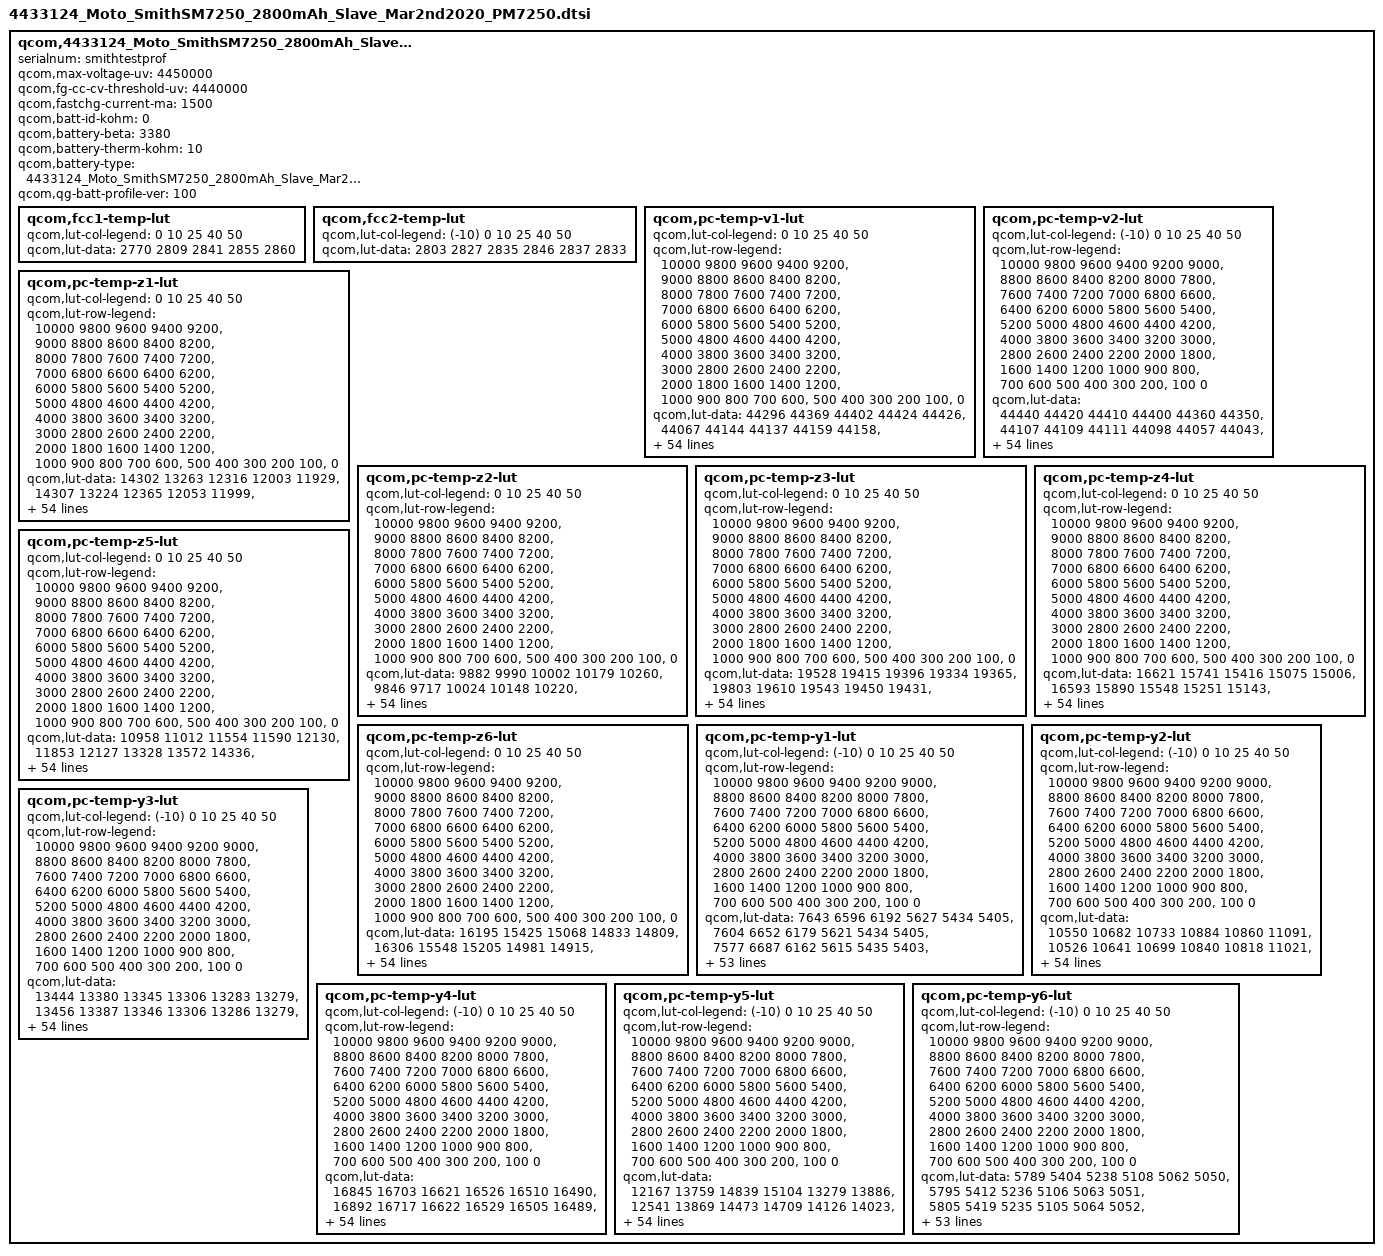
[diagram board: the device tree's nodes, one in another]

qcom,4433124_Moto_SmithSM7250_2800mAh_Slave_Mar2nd2020 {
    /* 4433124_Moto_SmithSM7250_2800mAh_Slave_Mar2nd2020 */
    serialnum = "smithtestprof";
    qcom,max-voltage-uv = <4450000>;
    qcom,fg-cc-cv-threshold-uv = <4440000>;
    qcom,fastchg-current-ma = <1500>;
    qcom,batt-id-kohm = <0>;
    qcom,battery-beta = <3380>;
    qcom,battery-therm-kohm = <10>;
    qcom,battery-type = "4433124_Moto_SmithSM7250_2800mAh_Slave_Mar2nd2020";
    qcom,qg-batt-profile-ver = <100>;

	qcom,fcc1-temp-lut {
		qcom,lut-col-legend = <0 10 25 40 50>;
		qcom,lut-data = <2770 2809 2841 2855 2860>;
	};

	qcom,fcc2-temp-lut {
		qcom,lut-col-legend = <(-10) 0 10 25 40 50>;
		qcom,lut-data = <2803 2827 2835 2846 2837 2833>;
	};

	qcom,pc-temp-v1-lut {
		qcom,lut-col-legend = <0 10 25 40 50>;
		qcom,lut-row-legend = <10000 9800 9600 9400 9200>,
			<9000 8800 8600 8400 8200>,
			<8000 7800 7600 7400 7200>,
			<7000 6800 6600 6400 6200>,
			<6000 5800 5600 5400 5200>,
			<5000 4800 4600 4400 4200>,
			<4000 3800 3600 3400 3200>,
			<3000 2800 2600 2400 2200>,
			<2000 1800 1600 1400 1200>,
			<1000 900 800 700 600>,
			<500 400 300 200 100>,
			<0>;
		qcom,lut-data = <44296 44369 44402 44424 44426>,
			<44067 44144 44137 44159 44158>,
			<43838 43911 43909 43924 43924>,
			<43610 43681 43691 43700 43703>,
			<43383 43456 43465 43477 43481>,
			<43147 43227 43236 43256 43263>,
			<42902 42988 43002 43030 43039>,
			<42657 42744 42760 42793 42805>,
			<42412 42500 42516 42552 42566>,
			<42168 42258 42275 42311 42326>,
			<41935 42020 42036 42069 42084>,
			<41713 41785 41800 41832 41847>,
			<41494 41554 41567 41602 41618>,
			<41275 41330 41339 41376 41393>,
			<41056 41112 41119 41155 41171>,
			<40843 40901 40907 40938 40954>,
			<40634 40694 40702 40732 40746>,
			<40432 40491 40503 40535 40550>,
			<40246 40301 40313 40346 40361>,
			<40068 40124 40137 40166 40183>,
			<39894 39947 39964 39992 40012>,
			<39728 39758 39763 39793 39814>,
			<39554 39563 39530 39553 39570>,
			<39339 39348 39308 39325 39336>,
			<39095 39091 39099 39131 39145>,
			<38909 38880 38914 38960 38979>,
			<38777 38762 38789 38832 38853>,
			<38672 38675 38696 38736 38758>,
			<38588 38592 38611 38647 38667>,
			<38521 38512 38528 38552 38563>,
			<38459 38439 38450 38462 38460>,
			<38398 38371 38374 38377 38371>,
			<38343 38309 38301 38297 38294>,
			<38293 38251 38234 38222 38218>,
			<38249 38200 38172 38151 38140>,
			<38207 38151 38113 38084 38063>,
			<38172 38106 38061 38021 37992>,
			<38134 38062 38014 37962 37926>,
			<38078 38002 37952 37892 37848>,
			<37997 37923 37866 37803 37749>,
			<37901 37828 37764 37701 37636>,
			<37782 37714 37655 37587 37517>,
			<37641 37576 37529 37456 37384>,
			<37473 37405 37368 37296 37221>,
			<37316 37249 37212 37152 37081>,
			<37197 37139 37101 37048 36986>,
			<37170 37107 37071 37013 36954>,
			<37135 37080 37048 36995 36933>,
			<37106 37059 37030 36975 36912>,
			<37075 37027 36989 36926 36853>,
			<36956 36866 36787 36685 36593>,
			<36561 36441 36356 36247 36153>,
			<35992 35856 35778 35669 35574>,
			<35200 35022 34993 34884 34787>,
			<33836 33705 33780 33679 33580>,
			<30000 30000 30000 30000 30000>;
	};

	qcom,pc-temp-v2-lut {
		qcom,lut-col-legend = <(-10) 0 10 25 40 50>;
		qcom,lut-row-legend = <10000 9800 9600 9400 9200 9000>,
			<8800 8600 8400 8200 8000 7800>,
			<7600 7400 7200 7000 6800 6600>,
			<6400 6200 6000 5800 5600 5400>,
			<5200 5000 4800 4600 4400 4200>,
			<4000 3800 3600 3400 3200 3000>,
			<2800 2600 2400 2200 2000 1800>,
			<1600 1400 1200 1000 900 800>,
			<700 600 500 400 300 200>,
			<100 0>;
		qcom,lut-data = <44440 44420 44410 44400 44360 44350>,
			<44107 44109 44111 44098 44057 44043>,
			<43809 43827 43837 43820 43777 43760>,
			<43554 43578 43590 43567 43522 43504>,
			<43338 43362 43371 43340 43294 43274>,
			<43122 43142 43149 43111 43065 43045>,
			<42889 42902 42911 42871 42826 42809>,
			<42649 42656 42668 42628 42585 42570>,
			<42411 42412 42424 42383 42343 42330>,
			<42170 42168 42177 42138 42100 42088>,
			<41930 41928 41933 41896 41860 41850>,
			<41692 41690 41692 41659 41623 41615>,
			<41454 41457 41456 41426 41391 41386>,
			<41213 41231 41225 41197 41163 41160>,
			<40970 41011 41001 40972 40941 40939>,
			<40726 40791 40782 40755 40727 40725>,
			<40479 40570 40573 40546 40521 40517>,
			<40231 40344 40367 40343 40323 40317>,
			<39986 40101 40164 40152 40136 40129>,
			<39738 39842 39963 39968 39956 39950>,
			<39516 39602 39745 39769 39764 39762>,
			<39332 39384 39491 39546 39553 39557>,
			<39169 39186 39247 39324 39338 39349>,
			<39006 39008 39051 39107 39126 39138>,
			<38846 38847 38879 38899 38918 38927>,
			<38697 38702 38728 38736 38753 38760>,
			<38558 38571 38593 38606 38625 38634>,
			<38428 38452 38474 38494 38514 38524>,
			<38307 38341 38367 38390 38410 38419>,
			<38192 38238 38271 38296 38315 38321>,
			<38091 38143 38182 38209 38229 38233>,
			<38000 38055 38098 38128 38152 38156>,
			<37922 37975 38019 38052 38077 38078>,
			<37862 37907 37946 37983 37999 37993>,
			<37815 37846 37876 37916 37920 37904>,
			<37771 37795 37814 37841 37834 37808>,
			<37728 37755 37759 37761 37743 37705>,
			<37685 37714 37701 37679 37649 37601>,
			<37635 37660 37636 37598 37554 37502>,
			<37579 37594 37564 37513 37458 37404>,
			<37505 37514 37478 37421 37363 37307>,
			<37376 37407 37371 37318 37270 37211>,
			<37236 37275 37239 37181 37136 37082>,
			<37126 37113 37092 37052 36990 36934>,
			<37016 36974 36977 36970 36922 36865>,
			<36916 36868 36889 36897 36850 36794>,
			<36865 36823 36859 36876 36834 36774>,
			<36819 36785 36834 36857 36826 36777>,
			<36770 36734 36796 36835 36801 36740>,
			<36712 36650 36713 36756 36713 36648>,
			<36627 36439 36462 36459 36409 36299>,
			<36430 35983 35933 35938 35903 35798>,
			<35958 35298 35228 35265 35248 35138>,
			<35225 34276 34232 34311 34366 34251>,
			<34124 32807 32852 33186 33117 32969>,
			<32439 30056 29520 29519 29517 29516>;
	};

	qcom,pc-temp-z1-lut {
		qcom,lut-col-legend = <0 10 25 40 50>;
		qcom,lut-row-legend = <10000 9800 9600 9400 9200>,
			<9000 8800 8600 8400 8200>,
			<8000 7800 7600 7400 7200>,
			<7000 6800 6600 6400 6200>,
			<6000 5800 5600 5400 5200>,
			<5000 4800 4600 4400 4200>,
			<4000 3800 3600 3400 3200>,
			<3000 2800 2600 2400 2200>,
			<2000 1800 1600 1400 1200>,
			<1000 900 800 700 600>,
			<500 400 300 200 100>,
			<0>;
		qcom,lut-data = <14302 13263 12316 12003 11929>,
			<14307 13224 12365 12053 11999>,
			<14308 13223 12361 12056 12003>,
			<14288 13219 12354 12057 12006>,
			<14247 13200 12346 12057 12006>,
			<14219 13176 12337 12054 12003>,
			<14200 13158 12329 12051 12002>,
			<14181 13141 12320 12051 12002>,
			<14155 13124 12314 12050 12003>,
			<14127 13103 12311 12050 12002>,
			<14105 13088 12309 12049 12001>,
			<14086 13082 12307 12048 12001>,
			<14069 13079 12305 12047 12001>,
			<14050 13075 12305 12047 12001>,
			<14032 13072 12305 12047 12002>,
			<14015 13068 12305 12048 12003>,
			<13998 13061 12305 12049 12004>,
			<13988 13053 12306 12050 12005>,
			<13988 13050 12307 12052 12007>,
			<13989 13049 12308 12054 12009>,
			<13991 13049 12309 12055 12011>,
			<13993 13052 12310 12057 12013>,
			<13995 13057 12313 12059 12015>,
			<14001 13063 12317 12060 12017>,
			<14011 13068 12320 12063 12019>,
			<14019 13074 12324 12066 12021>,
			<14027 13081 12329 12069 12023>,
			<14032 13089 12336 12073 12026>,
			<14031 13096 12343 12076 12030>,
			<14025 13102 12350 12080 12033>,
			<14022 13109 12356 12085 12036>,
			<14026 13119 12363 12089 12040>,
			<14033 13131 12369 12093 12043>,
			<14039 13141 12376 12097 12047>,
			<14047 13149 12382 12102 12052>,
			<14056 13159 12389 12107 12056>,
			<14071 13169 12396 12111 12059>,
			<14090 13181 12403 12115 12061>,
			<14111 13195 12410 12118 12064>,
			<14134 13211 12419 12122 12067>,
			<14162 13227 12428 12126 12070>,
			<14198 13240 12436 12130 12073>,
			<14239 13253 12444 12134 12076>,
			<14295 13280 12452 12136 12077>,
			<14290 13295 12463 12139 12078>,
			<14281 13298 12471 12142 12079>,
			<14282 13302 12470 12141 12079>,
			<14305 13310 12469 12142 12079>,
			<14319 13306 12473 12142 12081>,
			<14309 13346 12483 12146 12083>,
			<14370 13349 12494 12150 12086>,
			<14367 13369 12504 12158 12092>,
			<14396 13413 12520 12166 12099>,
			<14439 13440 12546 12181 12112>,
			<14439 13440 12546 12181 12112>,
			<14439 13440 12546 12181 12112>;
	};

	qcom,pc-temp-z2-lut {
		qcom,lut-col-legend = <0 10 25 40 50>;
		qcom,lut-row-legend = <10000 9800 9600 9400 9200>,
			<9000 8800 8600 8400 8200>,
			<8000 7800 7600 7400 7200>,
			<7000 6800 6600 6400 6200>,
			<6000 5800 5600 5400 5200>,
			<5000 4800 4600 4400 4200>,
			<4000 3800 3600 3400 3200>,
			<3000 2800 2600 2400 2200>,
			<2000 1800 1600 1400 1200>,
			<1000 900 800 700 600>,
			<500 400 300 200 100>,
			<0>;
		qcom,lut-data = <9882 9990 10002 10179 10260>,
			<9846 9717 10024 10148 10220>,
			<9817 9850 10017 10157 10231>,
			<9793 9894 10004 10160 10234>,
			<9772 9867 9980 10146 10227>,
			<9756 9833 9938 10075 10182>,
			<9742 9809 9903 10027 10143>,
			<9733 9790 9871 10018 10126>,
			<9730 9780 9852 10013 10116>,
			<9728 9775 9860 10014 10118>,
			<9737 9773 9882 10023 10136>,
			<9812 9781 9897 10033 10145>,
			<9872 9803 9905 10045 10144>,
			<9842 9820 9915 10058 10142>,
			<9779 9833 9929 10070 10153>,
			<9761 9844 9947 10081 10187>,
			<9775 9853 9963 10090 10201>,
			<9795 9861 9978 10096 10193>,
			<9814 9872 9993 10103 10178>,
			<9834 9892 10010 10115 10156>,
			<9839 9906 10029 10134 10126>,
			<9836 9905 10063 10183 10142>,
			<9833 9903 10125 10372 10401>,
			<9838 9906 10157 10509 10615>,
			<9854 9943 10147 10425 10553>,
			<9865 9972 10124 10257 10412>,
			<9871 9964 10092 10173 10327>,
			<9876 9947 10042 10125 10271>,
			<9881 9942 10020 10105 10246>,
			<9885 9942 10032 10222 10317>,
			<9889 9943 10054 10390 10425>,
			<9893 9945 10086 10391 10406>,
			<9898 9949 10133 10282 10238>,
			<9900 9953 10149 10201 10129>,
			<9903 9956 10112 10165 10104>,
			<9905 9960 10074 10145 10091>,
			<9906 9965 10078 10161 10109>,
			<9908 9971 10101 10226 10180>,
			<9912 9976 10124 10278 10251>,
			<9918 9982 10151 10308 10313>,
			<9924 9987 10174 10337 10374>,
			<9926 9993 10184 10379 10426>,
			<9929 9998 10190 10421 10476>,
			<9947 10002 10193 10432 10542>,
			<10107 10071 10215 10383 10492>,
			<10204 10143 10245 10280 10312>,
			<10275 10166 10213 10278 10314>,
			<10293 10189 10196 10282 10330>,
			<10290 10389 10156 10284 10361>,
			<10281 10690 10175 10334 10438>,
			<10291 10407 10221 10366 10247>,
			<10166 10282 10150 10162 10093>,
			<9969 10181 10098 10068 10053>,
			<9853 10014 10033 9980 10004>,
			<9853 10014 10033 9980 10004>,
			<9853 10014 10033 9980 10004>;
	};

	qcom,pc-temp-z3-lut {
		qcom,lut-col-legend = <0 10 25 40 50>;
		qcom,lut-row-legend = <10000 9800 9600 9400 9200>,
			<9000 8800 8600 8400 8200>,
			<8000 7800 7600 7400 7200>,
			<7000 6800 6600 6400 6200>,
			<6000 5800 5600 5400 5200>,
			<5000 4800 4600 4400 4200>,
			<4000 3800 3600 3400 3200>,
			<3000 2800 2600 2400 2200>,
			<2000 1800 1600 1400 1200>,
			<1000 900 800 700 600>,
			<500 400 300 200 100>,
			<0>;
		qcom,lut-data = <19528 19415 19396 19334 19365>,
			<19803 19610 19543 19450 19431>,
			<19968 19729 19582 19492 19465>,
			<20030 19784 19604 19522 19484>,
			<20067 19813 19627 19534 19494>,
			<20085 19828 19646 19542 19502>,
			<20095 19832 19651 19545 19505>,
			<20100 19833 19652 19542 19503>,
			<20098 19833 19653 19538 19498>,
			<20095 19820 19642 19533 19494>,
			<20096 19801 19615 19526 19490>,
			<20113 19780 19597 19517 19485>,
			<20127 19757 19588 19505 19475>,
			<20091 19740 19579 19492 19464>,
			<20012 19727 19566 19483 19457>,
			<19973 19719 19552 19476 19451>,
			<19960 19717 19540 19467 19443>,
			<19949 19716 19530 19452 19430>,
			<19923 19713 19521 19437 19415>,
			<19892 19700 19510 19426 19397>,
			<19884 19691 19501 19417 19378>,
			<19907 19694 19504 19418 19376>,
			<19936 19702 19528 19445 19406>,
			<19957 19711 19542 19466 19430>,
			<19975 19724 19539 19457 19423>,
			<19980 19732 19532 19435 19405>,
			<19971 19724 19521 19414 19386>,
			<19956 19705 19502 19390 19360>,
			<19943 19693 19485 19377 19346>,
			<19930 19685 19472 19391 19388>,
			<19921 19680 19463 19416 19450>,
			<19916 19679 19470 19436 19457>,
			<19912 19678 19494 19455 19438>,
			<19908 19678 19510 19463 19420>,
			<19904 19678 19517 19451 19404>,
			<19898 19678 19520 19432 19389>,
			<19892 19676 19513 19418 19377>,
			<19884 19672 19492 19406 19366>,
			<19875 19666 19483 19397 19363>,
			<19864 19659 19482 19391 19364>,
			<19851 19649 19481 19388 19367>,
			<19833 19633 19470 19389 19372>,
			<19810 19617 19453 19392 19381>,
			<19784 19611 19451 19404 19398>,
			<19672 19575 19443 19399 19395>,
			<19594 19527 19428 19367 19357>,
			<19358 19499 19418 19366 19343>,
			<19345 19489 19415 19355 19340>,
			<19334 19367 19397 19349 19335>,
			<19313 19316 19390 19347 19333>,
			<19314 19368 19400 19397 19381>,
			<19344 19387 19448 19415 19389>,
			<19349 19395 19463 19417 19389>,
			<19416 19564 19466 19417 19389>,
			<19416 19564 19466 19417 19389>,
			<19416 19564 19466 19417 19389>;
	};

	qcom,pc-temp-z4-lut {
		qcom,lut-col-legend = <0 10 25 40 50>;
		qcom,lut-row-legend = <10000 9800 9600 9400 9200>,
			<9000 8800 8600 8400 8200>,
			<8000 7800 7600 7400 7200>,
			<7000 6800 6600 6400 6200>,
			<6000 5800 5600 5400 5200>,
			<5000 4800 4600 4400 4200>,
			<4000 3800 3600 3400 3200>,
			<3000 2800 2600 2400 2200>,
			<2000 1800 1600 1400 1200>,
			<1000 900 800 700 600>,
			<500 400 300 200 100>,
			<0>;
		qcom,lut-data = <16621 15741 15416 15075 15006>,
			<16593 15890 15548 15251 15143>,
			<16524 15752 15416 15189 15104>,
			<16320 15610 15238 15066 15002>,
			<16006 15454 15136 14991 14934>,
			<15787 15313 15056 14941 14889>,
			<15627 15218 14993 14897 14851>,
			<15497 15143 14942 14853 14818>,
			<15397 15089 14902 14818 14791>,
			<15313 15048 14876 14803 14778>,
			<15216 15015 14856 14795 14771>,
			<15087 14980 14841 14788 14765>,
			<15009 14948 14828 14781 14758>,
			<15020 14926 14818 14774 14752>,
			<15047 14913 14810 14765 14745>,
			<15052 14900 14802 14756 14737>,
			<15020 14885 14795 14749 14730>,
			<14992 14869 14787 14744 14723>,
			<14994 14857 14779 14740 14719>,
			<14999 14845 14772 14734 14717>,
			<14997 14839 14766 14728 14715>,
			<14946 14843 14773 14730 14718>,
			<14897 14856 14813 14767 14753>,
			<14923 14883 14863 14817 14800>,
			<15000 14967 14926 14878 14854>,
			<15048 15029 14981 14939 14909>,
			<15070 15027 14986 14950 14920>,
			<15082 15017 14979 14948 14917>,
			<15078 15005 14969 14943 14911>,
			<15062 14987 14957 14913 14851>,
			<15045 14967 14941 14861 14763>,
			<15027 14948 14913 14816 14740>,
			<15007 14929 14867 14769 14733>,
			<14991 14910 14832 14749 14731>,
			<14978 14890 14807 14748 14731>,
			<14963 14873 14791 14747 14731>,
			<14946 14861 14788 14746 14730>,
			<14929 14851 14786 14745 14725>,
			<14911 14843 14786 14745 14724>,
			<14893 14836 14794 14764 14742>,
			<14874 14828 14801 14783 14760>,
			<14855 14817 14801 14780 14754>,
			<14833 14803 14800 14768 14736>,
			<14805 14784 14794 14756 14724>,
			<14778 14748 14763 14741 14712>,
			<14785 14730 14731 14733 14711>,
			<15041 14741 14726 14725 14714>,
			<15044 14738 14707 14711 14694>,
			<15048 14861 14694 14682 14663>,
			<15063 14909 14686 14666 14651>,
			<15034 14858 14711 14671 14669>,
			<15070 14869 14693 14681 14682>,
			<15066 14873 14687 14691 14694>,
			<15027 14725 14698 14703 14707>,
			<15027 14725 14698 14703 14707>,
			<15027 14725 14698 14703 14707>;
	};

	qcom,pc-temp-z5-lut {
		qcom,lut-col-legend = <0 10 25 40 50>;
		qcom,lut-row-legend = <10000 9800 9600 9400 9200>,
			<9000 8800 8600 8400 8200>,
			<8000 7800 7600 7400 7200>,
			<7000 6800 6600 6400 6200>,
			<6000 5800 5600 5400 5200>,
			<5000 4800 4600 4400 4200>,
			<4000 3800 3600 3400 3200>,
			<3000 2800 2600 2400 2200>,
			<2000 1800 1600 1400 1200>,
			<1000 900 800 700 600>,
			<500 400 300 200 100>,
			<0>;
		qcom,lut-data = <10958 11012 11554 11590 12130>,
			<11853 12127 13328 13572 14336>,
			<12471 12998 13929 14770 15694>,
			<12788 13574 14366 16000 17129>,
			<13017 13940 14950 16738 18202>,
			<13275 14246 15573 17180 18977>,
			<13546 14604 16181 17706 19800>,
			<13844 14951 16862 18655 20919>,
			<14175 15122 17340 19674 22118>,
			<14562 15180 17450 20318 23158>,
			<15143 15245 17505 20822 24172>,
			<16227 15453 17656 20986 24574>,
			<16963 15827 18154 20788 24289>,
			<16686 16177 18515 20571 23943>,
			<16090 16467 18510 20868 24394>,
			<16011 16832 18490 21729 25911>,
			<16984 17602 18543 21994 26499>,
			<17838 18647 18957 21220 25585>,
			<17511 19116 19440 20505 24097>,
			<16704 19238 19736 20557 22191>,
			<16609 19400 20071 20850 19902>,
			<19338 20748 21787 22154 20159>,
			<23364 23506 27673 29534 29597>,
			<27654 25617 31013 35082 37395>,
			<32431 27441 28760 31294 33374>,
			<33883 28434 24848 23582 24466>,
			<31564 26656 21976 19172 19187>,
			<28469 22944 19446 16227 15653>,
			<26484 21200 17766 14980 14101>,
			<24810 20427 16670 15282 17213>,
			<24212 20082 16015 16017 21928>,
			<24160 20210 16315 17507 22502>,
			<24135 20574 17707 20657 21564>,
			<24190 21107 19416 22260 20851>,
			<24393 22137 22136 22368 20537>,
			<24550 23208 24281 22420 20352>,
			<24609 24150 24091 22363 20355>,
			<24668 24946 23252 22104 20416>,
			<24942 25095 23005 21729 20423>,
			<25650 25023 23707 21014 19994>,
			<26004 24883 24349 20107 19557>,
			<25118 23536 22190 19063 19631>,
			<24404 22086 18674 18171 20048>,
			<24654 23547 19058 20400 25117>,
			<22559 23876 20319 20754 26080>,
			<18802 21370 20566 16935 17505>,
			<11548 17573 18946 17077 15727>,
			<11404 16555 19449 16564 16447>,
			<11287 12036 17893 18226 19370>,
			<11106 11305 17718 19298 20894>,
			<11231 12073 17615 28108 30060>,
			<11289 12281 20912 26954 27485>,
			<11308 12364 22129 24351 24356>,
			<11917 23636 20542 21049 20849>,
			<11917 23636 20542 21049 20849>,
			<11917 23636 20542 21049 20849>;
	};

	qcom,pc-temp-z6-lut {
		qcom,lut-col-legend = <0 10 25 40 50>;
		qcom,lut-row-legend = <10000 9800 9600 9400 9200>,
			<9000 8800 8600 8400 8200>,
			<8000 7800 7600 7400 7200>,
			<7000 6800 6600 6400 6200>,
			<6000 5800 5600 5400 5200>,
			<5000 4800 4600 4400 4200>,
			<4000 3800 3600 3400 3200>,
			<3000 2800 2600 2400 2200>,
			<2000 1800 1600 1400 1200>,
			<1000 900 800 700 600>,
			<500 400 300 200 100>,
			<0>;
		qcom,lut-data = <16195 15425 15068 14833 14809>,
			<16306 15548 15205 14981 14915>,
			<16342 15553 15163 14967 14909>,
			<16275 15550 15107 14937 14880>,
			<16140 15494 15074 14915 14860>,
			<16041 15423 15048 14897 14845>,
			<15963 15380 15025 14880 14831>,
			<15897 15344 15004 14861 14816>,
			<15841 15312 14985 14844 14803>,
			<15792 15284 14963 14833 14794>,
			<15746 15257 14942 14826 14789>,
			<15702 15229 14927 14818 14783>,
			<15663 15201 14916 14808 14774>,
			<15631 15181 14906 14798 14765>,
			<15602 15169 14895 14789 14758>,
			<15577 15158 14884 14781 14751>,
			<15554 15149 14874 14772 14744>,
			<15535 15140 14865 14762 14734>,
			<15521 15131 14857 14752 14724>,
			<15510 15119 14848 14743 14713>,
			<15502 15112 14840 14736 14702>,
			<15495 15116 14844 14737 14702>,
			<15492 15127 14874 14768 14733>,
			<15510 15145 14904 14800 14767>,
			<15559 15190 14930 14819 14785>,
			<15582 15221 14950 14834 14797>,
			<15586 15217 14950 14835 14798>,
			<15589 15206 14937 14823 14785>,
			<15585 15195 14925 14810 14773>,
			<15574 15186 14914 14803 14768>,
			<15563 15177 14903 14797 14765>,
			<15554 15169 14896 14790 14759>,
			<15546 15162 14890 14782 14747>,
			<15540 15155 14884 14775 14737>,
			<15534 15149 14879 14767 14729>,
			<15528 15144 14875 14760 14722>,
			<15522 15140 14867 14752 14714>,
			<15517 15136 14857 14744 14706>,
			<15513 15133 14854 14741 14704>,
			<15510 15131 14858 14746 14712>,
			<15505 15128 14862 14752 14721>,
			<15499 15121 14858 14751 14720>,
			<15491 15112 14850 14748 14719>,
			<15481 15107 14846 14748 14722>,
			<15430 15080 14831 14742 14715>,
			<15401 15052 14811 14721 14695>,
			<15393 15045 14804 14717 14691>,
			<15390 15041 14794 14705 14679>,
			<15389 15033 14780 14689 14663>,
			<15393 15033 14774 14681 14656>,
			<15394 15046 14793 14710 14690>,
			<15439 15068 14813 14727 14703>,
			<15455 15085 14823 14735 14711>,
			<15497 15123 14835 14743 14719>,
			<15497 15123 14835 14743 14719>,
			<15497 15123 14835 14743 14719>;
	};

	qcom,pc-temp-y1-lut {
		qcom,lut-col-legend = <(-10) 0 10 25 40 50>;
		qcom,lut-row-legend = <10000 9800 9600 9400 9200 9000>,
			<8800 8600 8400 8200 8000 7800>,
			<7600 7400 7200 7000 6800 6600>,
			<6400 6200 6000 5800 5600 5400>,
			<5200 5000 4800 4600 4400 4200>,
			<4000 3800 3600 3400 3200 3000>,
			<2800 2600 2400 2200 2000 1800>,
			<1600 1400 1200 1000 900 800>,
			<700 600 500 400 300 200>,
			<100 0>;
		qcom,lut-data = <7643 6596 6192 5627 5434 5405>,
			<7604 6652 6179 5621 5434 5405>,
			<7577 6687 6162 5615 5435 5403>,
			<7560 6706 6144 5610 5435 5402>,
			<7551 6714 6128 5604 5435 5401>,
			<7549 6715 6121 5600 5434 5400>,
			<7559 6700 6119 5595 5433 5400>,
			<7574 6678 6117 5590 5432 5400>,
			<7575 6670 6113 5587 5430 5400>,
			<7563 6666 6105 5585 5429 5400>,
			<7553 6664 6096 5583 5428 5400>,
			<7548 6669 6086 5583 5429 5400>,
			<7545 6676 6077 5582 5430 5400>,
			<7548 6675 6072 5581 5430 5400>,
			<7565 6671 6069 5579 5431 5402>,
			<7576 6669 6065 5578 5431 5402>,
			<7577 6675 6060 5579 5432 5402>,
			<7578 6681 6057 5581 5433 5401>,
			<7575 6678 6058 5583 5433 5402>,
			<7561 6666 6060 5585 5433 5403>,
			<7550 6661 6062 5587 5434 5404>,
			<7546 6661 6065 5589 5435 5405>,
			<7544 6662 6068 5592 5436 5405>,
			<7545 6663 6071 5595 5438 5406>,
			<7554 6666 6075 5598 5440 5408>,
			<7564 6669 6078 5602 5442 5410>,
			<7581 6671 6080 5605 5444 5412>,
			<7598 6673 6082 5609 5447 5413>,
			<7596 6676 6086 5613 5449 5415>,
			<7577 6680 6094 5618 5452 5417>,
			<7566 6685 6101 5622 5454 5419>,
			<7569 6700 6107 5627 5455 5421>,
			<7573 6711 6113 5632 5457 5423>,
			<7571 6709 6116 5639 5460 5426>,
			<7559 6705 6120 5645 5464 5429>,
			<7548 6705 6123 5649 5467 5431>,
			<7543 6716 6125 5652 5468 5432>,
			<7540 6724 6128 5655 5470 5433>,
			<7540 6722 6132 5658 5471 5435>,
			<7542 6718 6136 5661 5473 5435>,
			<7546 6724 6141 5664 5474 5436>,
			<7580 6775 6148 5667 5475 5437>,
			<7607 6786 6155 5668 5477 5438>,
			<7575 6766 6163 5669 5478 5440>,
			<7586 6782 6174 5675 5479 5441>,
			<7625 6782 6195 5677 5482 5443>,
			<7628 6769 6204 5682 5483 5444>,
			<7607 6773 6214 5684 5484 5445>,
			<7619 6795 6218 5685 5485 5445>,
			<7630 6779 6217 5684 5485 5446>,
			<7664 6803 6236 5686 5485 5447>,
			<7816 6811 6246 5694 5490 5450>,
			<7890 6930 6290 5708 5495 5457>,
			<8109 7068 6337 5724 5504 5462>,
			<8109 7068 6337 5724 5504 5462>,
			<8109 7068 6337 5724 5504 5462>;
	};

	qcom,pc-temp-y2-lut {
		qcom,lut-col-legend = <(-10) 0 10 25 40 50>;
		qcom,lut-row-legend = <10000 9800 9600 9400 9200 9000>,
			<8800 8600 8400 8200 8000 7800>,
			<7600 7400 7200 7000 6800 6600>,
			<6400 6200 6000 5800 5600 5400>,
			<5200 5000 4800 4600 4400 4200>,
			<4000 3800 3600 3400 3200 3000>,
			<2800 2600 2400 2200 2000 1800>,
			<1600 1400 1200 1000 900 800>,
			<700 600 500 400 300 200>,
			<100 0>;
		qcom,lut-data = <10550 10682 10733 10884 10860 11091>,
			<10526 10641 10699 10840 10818 11021>,
			<10499 10600 10667 10796 10777 10942>,
			<10473 10563 10637 10756 10739 10865>,
			<10451 10531 10611 10721 10707 10802>,
			<10437 10507 10587 10693 10681 10762>,
			<10429 10486 10566 10670 10662 10743>,
			<10424 10472 10548 10652 10646 10728>,
			<10424 10470 10537 10643 10633 10711>,
			<10426 10469 10530 10638 10621 10691>,
			<10430 10469 10527 10632 10613 10673>,
			<10434 10473 10534 10618 10606 10653>,
			<10439 10480 10544 10607 10602 10639>,
			<10446 10484 10551 10607 10602 10638>,
			<10453 10486 10556 10613 10607 10644>,
			<10465 10491 10564 10622 10615 10653>,
			<10495 10521 10574 10644 10653 10675>,
			<10531 10557 10589 10677 10708 10709>,
			<10539 10568 10614 10727 10755 10745>,
			<10540 10574 10652 10795 10801 10788>,
			<10541 10581 10670 10834 10855 10844>,
			<10546 10594 10675 10857 10932 10945>,
			<10555 10608 10679 10868 10987 11022>,
			<10560 10622 10687 10864 10968 11011>,
			<10565 10637 10699 10856 10918 10975>,
			<10568 10646 10711 10857 10907 10965>,
			<10571 10652 10727 10879 10949 11000>,
			<10572 10656 10737 10904 10994 11049>,
			<10574 10657 10735 10923 11009 11086>,
			<10575 10658 10732 10939 11019 11124>,
			<10577 10658 10731 10950 11041 11177>,
			<10588 10654 10731 10959 11098 11271>,
			<10603 10649 10731 10963 11156 11333>,
			<10598 10644 10729 10956 11199 11312>,
			<10562 10636 10724 10942 11234 11257>,
			<10522 10625 10717 10929 11229 11208>,
			<10489 10604 10710 10916 11164 11154>,
			<10455 10580 10700 10901 11097 11125>,
			<10420 10558 10688 10877 11054 11130>,
			<10388 10534 10672 10857 11021 11140>,
			<10330 10502 10654 10857 11010 11120>,
			<9992 10457 10632 10862 11007 11013>,
			<9712 10401 10601 10830 10972 10999>,
			<9681 10330 10560 10792 10894 11028>,
			<9668 10260 10520 10793 10868 10890>,
			<9663 10174 10475 10733 10809 10827>,
			<9660 9926 10441 10707 10729 10764>,
			<9657 9825 10418 10686 10797 10899>,
			<9655 9741 10404 10728 10865 10945>,
			<9652 9678 10392 10734 10855 10928>,
			<9649 9658 10307 10695 10756 10756>,
			<9647 9651 10144 10644 10710 10731>,
			<9646 9648 9906 10584 10664 10722>,
			<9646 9649 9662 10464 10574 10618>,
			<9646 9649 9662 10464 10574 10618>,
			<9646 9649 9662 10464 10574 10618>;
	};

	qcom,pc-temp-y3-lut {
		qcom,lut-col-legend = <(-10) 0 10 25 40 50>;
		qcom,lut-row-legend = <10000 9800 9600 9400 9200 9000>,
			<8800 8600 8400 8200 8000 7800>,
			<7600 7400 7200 7000 6800 6600>,
			<6400 6200 6000 5800 5600 5400>,
			<5200 5000 4800 4600 4400 4200>,
			<4000 3800 3600 3400 3200 3000>,
			<2800 2600 2400 2200 2000 1800>,
			<1600 1400 1200 1000 900 800>,
			<700 600 500 400 300 200>,
			<100 0>;
		qcom,lut-data = <13444 13380 13345 13306 13283 13279>,
			<13456 13387 13346 13306 13286 13279>,
			<13472 13397 13348 13306 13288 13280>,
			<13489 13406 13349 13306 13291 13281>,
			<13503 13413 13351 13306 13293 13282>,
			<13511 13416 13353 13306 13294 13283>,
			<13513 13415 13356 13308 13295 13284>,
			<13515 13413 13358 13310 13297 13286>,
			<13518 13414 13358 13312 13297 13286>,
			<13523 13419 13358 13312 13298 13287>,
			<13527 13423 13358 13314 13299 13288>,
			<13531 13424 13358 13320 13299 13290>,
			<13534 13425 13358 13327 13299 13293>,
			<13534 13428 13358 13328 13300 13294>,
			<13535 13437 13361 13327 13300 13294>,
			<13535 13441 13365 13328 13300 13295>,
			<13525 13443 13372 13330 13305 13295>,
			<13507 13444 13377 13333 13311 13295>,
			<13494 13440 13378 13333 13314 13297>,
			<13482 13425 13377 13333 13315 13302>,
			<13475 13412 13375 13333 13315 13304>,
			<13473 13403 13366 13329 13310 13303>,
			<13472 13395 13354 13324 13303 13299>,
			<13469 13389 13349 13315 13297 13293>,
			<13465 13385 13345 13304 13290 13284>,
			<13461 13383 13341 13300 13288 13281>,
			<13455 13382 13336 13299 13287 13283>,
			<13449 13382 13333 13298 13287 13284>,
			<13443 13382 13335 13300 13286 13284>,
			<13439 13381 13339 13303 13285 13282>,
			<13433 13381 13340 13304 13285 13282>,
			<13418 13382 13340 13304 13285 13283>,
			<13403 13383 13340 13304 13286 13284>,
			<13402 13382 13340 13304 13287 13284>,
			<13414 13380 13340 13303 13287 13284>,
			<13429 13380 13341 13303 13287 13284>,
			<13444 13384 13341 13303 13287 13282>,
			<13459 13389 13341 13304 13286 13280>,
			<13475 13394 13343 13304 13286 13281>,
			<13491 13398 13345 13305 13286 13282>,
			<13498 13402 13346 13306 13288 13284>,
			<13492 13407 13346 13307 13293 13287>,
			<13487 13407 13347 13304 13290 13286>,
			<13543 13404 13348 13302 13282 13279>,
			<13610 13413 13348 13304 13285 13282>,
			<13682 13417 13352 13305 13288 13286>,
			<13770 13409 13353 13314 13303 13294>,
			<13939 13437 13371 13327 13308 13298>,
			<14192 13488 13389 13335 13308 13298>,
			<14679 13612 13400 13333 13307 13297>,
			<16081 13889 13406 13325 13303 13292>,
			<20543 15111 13422 13323 13303 13295>,
			<32277 20549 13557 13336 13308 13299>,
			<65535 39171 14758 13355 13322 13313>,
			<65535 39171 14758 13355 13322 13313>,
			<65535 39171 14758 13355 13322 13313>;
	};

	qcom,pc-temp-y4-lut {
		qcom,lut-col-legend = <(-10) 0 10 25 40 50>;
		qcom,lut-row-legend = <10000 9800 9600 9400 9200 9000>,
			<8800 8600 8400 8200 8000 7800>,
			<7600 7400 7200 7000 6800 6600>,
			<6400 6200 6000 5800 5600 5400>,
			<5200 5000 4800 4600 4400 4200>,
			<4000 3800 3600 3400 3200 3000>,
			<2800 2600 2400 2200 2000 1800>,
			<1600 1400 1200 1000 900 800>,
			<700 600 500 400 300 200>,
			<100 0>;
		qcom,lut-data = <16845 16703 16621 16526 16510 16490>,
			<16892 16717 16622 16529 16505 16489>,
			<16942 16731 16624 16533 16501 16489>,
			<16989 16744 16626 16536 16500 16489>,
			<17030 16756 16627 16539 16499 16490>,
			<17056 16766 16629 16541 16499 16491>,
			<17072 16773 16631 16543 16500 16492>,
			<17083 16781 16632 16546 16503 16493>,
			<17093 16790 16638 16551 16506 16495>,
			<17101 16801 16651 16560 16510 16498>,
			<17110 16816 16667 16565 16515 16502>,
			<17120 16843 16685 16567 16522 16506>,
			<17129 16877 16707 16569 16529 16510>,
			<17127 16903 16729 16576 16539 16515>,
			<17109 16925 16754 16595 16550 16522>,
			<17098 16948 16783 16615 16559 16530>,
			<17106 16978 16824 16634 16564 16539>,
			<17118 17000 16860 16656 16571 16550>,
			<17097 16977 16874 16696 16592 16566>,
			<16986 16887 16884 16747 16628 16587>,
			<16909 16814 16881 16759 16640 16595>,
			<16897 16767 16789 16730 16637 16595>,
			<16890 16731 16681 16687 16630 16594>,
			<16876 16706 16634 16625 16595 16571>,
			<16855 16688 16601 16555 16528 16513>,
			<16836 16676 16593 16539 16508 16494>,
			<16823 16669 16594 16542 16511 16496>,
			<16812 16663 16595 16546 16516 16499>,
			<16798 16660 16597 16552 16525 16506>,
			<16781 16658 16600 16561 16539 16519>,
			<16773 16653 16604 16571 16554 16532>,
			<16789 16643 16612 16584 16573 16548>,
			<16814 16635 16618 16597 16584 16558>,
			<16823 16636 16615 16611 16584 16558>,
			<16826 16641 16610 16622 16582 16556>,
			<16831 16648 16610 16618 16578 16553>,
			<16843 16672 16612 16592 16568 16541>,
			<16861 16699 16615 16571 16556 16530>,
			<16878 16724 16618 16559 16542 16523>,
			<16896 16747 16621 16552 16529 16518>,
			<16919 16758 16626 16553 16531 16522>,
			<16966 16764 16631 16557 16547 16546>,
			<16995 16762 16624 16540 16531 16534>,
			<16987 16740 16608 16519 16489 16482>,
			<17004 16726 16613 16516 16492 16479>,
			<16989 16726 16617 16541 16510 16489>,
			<17011 16799 16652 16566 16534 16534>,
			<17025 16850 16692 16642 16694 16758>,
			<17068 16917 16763 16809 16839 16851>,
			<17139 17013 16847 16819 16810 16802>,
			<17262 17095 16848 16632 16603 16570>,
			<18296 17178 16805 16579 16553 16557>,
			<21765 19692 16985 16614 16576 16581>,
			<41436 44215 18176 16714 16648 16645>,
			<41436 44215 18176 16714 16648 16645>,
			<41436 44215 18176 16714 16648 16645>;
	};

	qcom,pc-temp-y5-lut {
		qcom,lut-col-legend = <(-10) 0 10 25 40 50>;
		qcom,lut-row-legend = <10000 9800 9600 9400 9200 9000>,
			<8800 8600 8400 8200 8000 7800>,
			<7600 7400 7200 7000 6800 6600>,
			<6400 6200 6000 5800 5600 5400>,
			<5200 5000 4800 4600 4400 4200>,
			<4000 3800 3600 3400 3200 3000>,
			<2800 2600 2400 2200 2000 1800>,
			<1600 1400 1200 1000 900 800>,
			<700 600 500 400 300 200>,
			<100 0>;
		qcom,lut-data = <12167 13759 14839 15104 13279 13886>,
			<12541 13869 14473 14709 14126 14023>,
			<12844 13919 14118 14167 14718 14108>,
			<13069 13918 13791 13604 15093 14155>,
			<13208 13876 13506 13144 15288 14174>,
			<13256 13798 13278 12912 15340 14178>,
			<13165 13347 13123 12849 15176 14156>,
			<13027 12759 12980 12802 14860 14104>,
			<13031 12616 12745 12658 14528 13937>,
			<13210 12581 12397 12378 14125 13499>,
			<13433 12547 12095 12269 13736 13286>,
			<13709 12496 11833 12645 13382 13472>,
			<13975 12455 11654 13064 13052 13700>,
			<14048 12571 11648 12941 12729 13645>,
			<14065 13099 11695 12488 12408 13333>,
			<14088 13702 11778 12297 12313 13030>,
			<14198 14366 12078 12282 12669 12736>,
			<14332 15025 12596 12276 13048 12528>,
			<14348 15528 13589 12369 13073 12591>,
			<14317 15966 15166 12700 13072 12907>,
			<14299 16095 15782 13302 13130 13410>,
			<14547 15681 15842 15096 14031 14810>,
			<14909 15161 15868 16459 14956 16017>,
			<14969 14942 15807 15943 15139 15716>,
			<14960 14798 15598 14773 15231 14799>,
			<14941 14769 15294 14173 15212 14508>,
			<14787 14977 14637 13856 14783 14856>,
			<14505 15240 14150 13718 14242 15170>,
			<14251 15366 14518 14063 13787 14750>,
			<14001 15455 15394 14675 13378 13805>,
			<13661 15616 15868 14895 13304 13532>,
			<12846 16045 16071 14967 13447 13643>,
			<11987 16379 16250 15033 13672 13836>,
			<11919 16094 16517 15102 14045 14360>,
			<12273 15433 16771 15188 14559 15110>,
			<12744 15251 16787 15505 15007 15257>,
			<13373 15435 16546 16338 15461 15012>,
			<14123 15589 16302 16747 15682 14832>,
			<14827 15557 16197 16555 15555 15033>,
			<15574 15457 16103 16239 15360 15548>,
			<15886 15342 15816 15996 15814 16345>,
			<13483 15188 15133 15774 17692 17704>,
			<11348 14735 14881 15597 17307 17826>,
			<11229 13740 14770 15315 15075 16869>,
			<10932 13670 14113 14880 13916 14809>,
			<10905 12945 14009 13192 12994 14360>,
			<10843 11573 13233 13542 15569 16124>,
			<11037 11543 13777 15061 16457 15234>,
			<11100 11451 14427 14986 14015 13697>,
			<11084 11492 14466 14262 13832 13668>,
			<11128 11381 13892 15200 14851 15420>,
			<9938 11287 13376 15272 16269 16178>,
			<9147 9571 12802 16145 15577 15080>,
			<8855 8892 10634 16707 16133 15323>,
			<8855 8892 10634 16707 16133 15323>,
			<8855 8892 10634 16707 16133 15323>;
	};

	qcom,pc-temp-y6-lut {
		qcom,lut-col-legend = <(-10) 0 10 25 40 50>;
		qcom,lut-row-legend = <10000 9800 9600 9400 9200 9000>,
			<8800 8600 8400 8200 8000 7800>,
			<7600 7400 7200 7000 6800 6600>,
			<6400 6200 6000 5800 5600 5400>,
			<5200 5000 4800 4600 4400 4200>,
			<4000 3800 3600 3400 3200 3000>,
			<2800 2600 2400 2200 2000 1800>,
			<1600 1400 1200 1000 900 800>,
			<700 600 500 400 300 200>,
			<100 0>;
		qcom,lut-data = <5789 5404 5238 5108 5062 5050>,
			<5795 5412 5236 5106 5063 5051>,
			<5805 5419 5235 5105 5064 5052>,
			<5815 5424 5235 5105 5066 5052>,
			<5823 5428 5234 5106 5067 5053>,
			<5827 5429 5234 5107 5068 5055>,
			<5826 5427 5235 5108 5070 5056>,
			<5824 5424 5235 5111 5071 5057>,
			<5824 5424 5236 5113 5073 5059>,
			<5825 5428 5238 5115 5074 5060>,
			<5826 5432 5241 5118 5076 5062>,
			<5827 5439 5245 5122 5079 5065>,
			<5828 5447 5250 5127 5081 5068>,
			<5827 5456 5256 5131 5084 5070>,
			<5822 5466 5264 5136 5087 5073>,
			<5816 5474 5274 5141 5091 5075>,
			<5811 5483 5290 5148 5095 5078>,
			<5804 5490 5303 5157 5101 5081>,
			<5788 5480 5307 5169 5110 5088>,
			<5752 5445 5309 5183 5121 5097>,
			<5730 5416 5307 5186 5124 5100>,
			<5728 5397 5274 5175 5120 5099>,
			<5727 5382 5235 5158 5112 5096>,
			<5725 5373 5219 5134 5096 5084>,
			<5720 5365 5207 5107 5072 5061>,
			<5718 5363 5203 5101 5066 5053>,
			<5717 5363 5201 5101 5066 5055>,
			<5716 5364 5200 5101 5067 5057>,
			<5716 5366 5202 5104 5069 5059>,
			<5718 5368 5207 5109 5073 5062>,
			<5721 5370 5211 5114 5077 5065>,
			<5727 5372 5215 5119 5083 5071>,
			<5736 5374 5217 5123 5087 5075>,
			<5750 5377 5219 5127 5088 5075>,
			<5773 5382 5220 5130 5088 5075>,
			<5800 5390 5221 5129 5087 5074>,
			<5834 5405 5224 5122 5084 5069>,
			<5875 5423 5226 5118 5081 5065>,
			<5922 5441 5230 5115 5077 5064>,
			<5978 5461 5235 5114 5073 5063>,
			<6031 5482 5240 5115 5075 5065>,
			<6073 5506 5246 5118 5084 5075>,
			<6122 5528 5247 5112 5077 5070>,
			<6205 5549 5248 5104 5059 5051>,
			<6319 5596 5257 5105 5063 5052>,
			<6427 5633 5268 5114 5070 5060>,
			<6539 5688 5285 5128 5088 5079>,
			<6707 5780 5317 5160 5138 5145>,
			<6957 5908 5358 5213 5179 5172>,
			<7420 6114 5401 5214 5171 5157>,
			<8667 6474 5423 5155 5108 5088>,
			<12454 7603 5474 5140 5095 5086>,
			<21786 12502 5804 5162 5106 5097>,
			<58476 32802 7294 5208 5138 5127>,
			<58476 32802 7294 5208 5138 5127>,
			<58476 32802 7294 5208 5138 5127>;
	};

};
